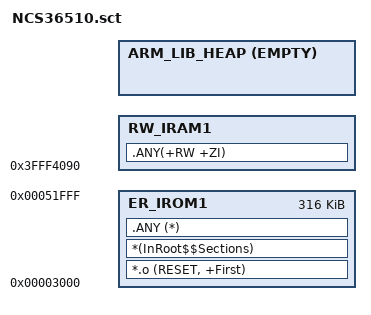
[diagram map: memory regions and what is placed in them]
#! armcc -E

LR_IROM1 0x00003000 0x0004F000  {    ; load region size_region
  ER_IROM1 0x00003000 0x0004F000  {  ; load address = execution address
   *.o (RESET, +First)
   *(InRoot$$Sections)
   .ANY (*)
  }

  ; no uvisor support at this time

  RW_IRAM1 0x3FFF4000 + 0x90 { ; 8_byte_aligned(35 vectors * 4 bytes each) = 0x90
    .ANY(+RW +ZI)
  }
  ARM_LIB_HEAP AlignExpr(+0, 8) ALIGN 8 EMPTY (0x3FFF4000 + 0xC000 - AlignExpr(ImageLimit(RW_IRAM1),8) ) {}
}
